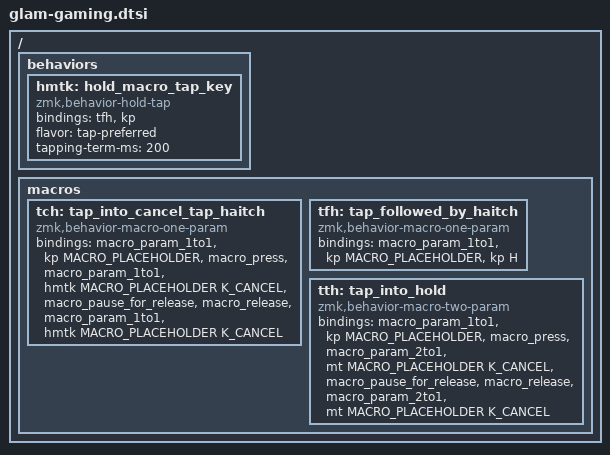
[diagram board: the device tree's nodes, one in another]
/*
 * Copyright (c) 2025 Allister MacLeod
 *
 * SPDX-License-Identifier: MIT
 */

// Devicetree include for sharing gaming behaviors and macros used by
// multiple keymaps.
// These behaviors are meant to work in tandem with the combos in
// glam-factorio-combos.dtsi

/ {
  behaviors {
    // Hold to invoke the tap-followed-by-H macro. For the use case of
    // sending VVH for Factorio flipping, use a no-op keycode like
    // K_CANCEL as the tap portion.
    hmtk: hold_macro_tap_key {
      compatible = "zmk,behavior-hold-tap";
      #binding-cells = <2>;
      bindings = <&tfh &kp>;
      flavor = "tap-preferred";
      tapping-term-ms = <200>;
    };
  };

  macros {
    // Tap the first key, but if held then tap again to cancel followed
    // by a tap of H.
    // This supposes that the first key is reversible or a toggle, like
    // the "flip entity" buttons in Factorio.
    tch: tap_into_cancel_tap_haitch {
      compatible = "zmk,behavior-macro-one-param";
      #binding-cells = <1>;
      bindings
        = <&macro_param_1to1>
        , <&kp MACRO_PLACEHOLDER>
        , <&macro_press>
        , <&macro_param_1to1>
        , <&hmtk MACRO_PLACEHOLDER K_CANCEL>
        , <&macro_pause_for_release>
        , <&macro_release>
        , <&macro_param_1to1>
        , <&hmtk MACRO_PLACEHOLDER K_CANCEL>
        ;
    };
    tfh: tap_followed_by_haitch {
      compatible = "zmk,behavior-macro-one-param";
      #binding-cells = <1>;
      bindings
        = <&macro_param_1to1>
        , <&kp MACRO_PLACEHOLDER>
        , <&kp H>
        ;
    };
    // Tap the first key immediately, followed by the second key if
    // held, using the "mod" hold of &mt for the second key.
    tth: tap_into_hold {
      compatible = "zmk,behavior-macro-two-param";
      #binding-cells = <2>;
      bindings
        = <&macro_param_1to1>
        , <&kp MACRO_PLACEHOLDER>
        , <&macro_press>
        , <&macro_param_2to1>
        , <&mt MACRO_PLACEHOLDER K_CANCEL>
        , <&macro_pause_for_release>
        , <&macro_release>
        , <&macro_param_2to1>
        , <&mt MACRO_PLACEHOLDER K_CANCEL>
        ;
    };
  };
};
